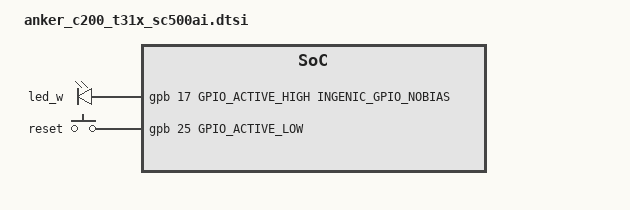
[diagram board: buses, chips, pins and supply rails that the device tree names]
// Anker C200 (T31X, SC500AI) per-board GPIO definitions.
// Injected into the kernel 4.4+ device tree; ignored on 3.10.

#include <dt-bindings/gpio/gpio.h>
#include <dt-bindings/input/input.h>
#include <dt-bindings/pinctrl/ingenic-pinctrl.h>

/ {
	gpio-leds {
		compatible = "gpio-leds";

		led_w {
			label = "led_w";
			gpios = <&gpb 17 GPIO_ACTIVE_HIGH INGENIC_GPIO_NOBIAS>;
			default-state = "off";
		};
	};
};

/ {
	gpio-keys {
		compatible = "gpio-keys";
		label = "gpio-keys";

		reset {
			label = "reset";
			linux,code = <KEY_ENTER>;
			gpios = <&gpb 25 GPIO_ACTIVE_LOW INGENIC_GPIO_PULLUP>;
		};
	};
};
